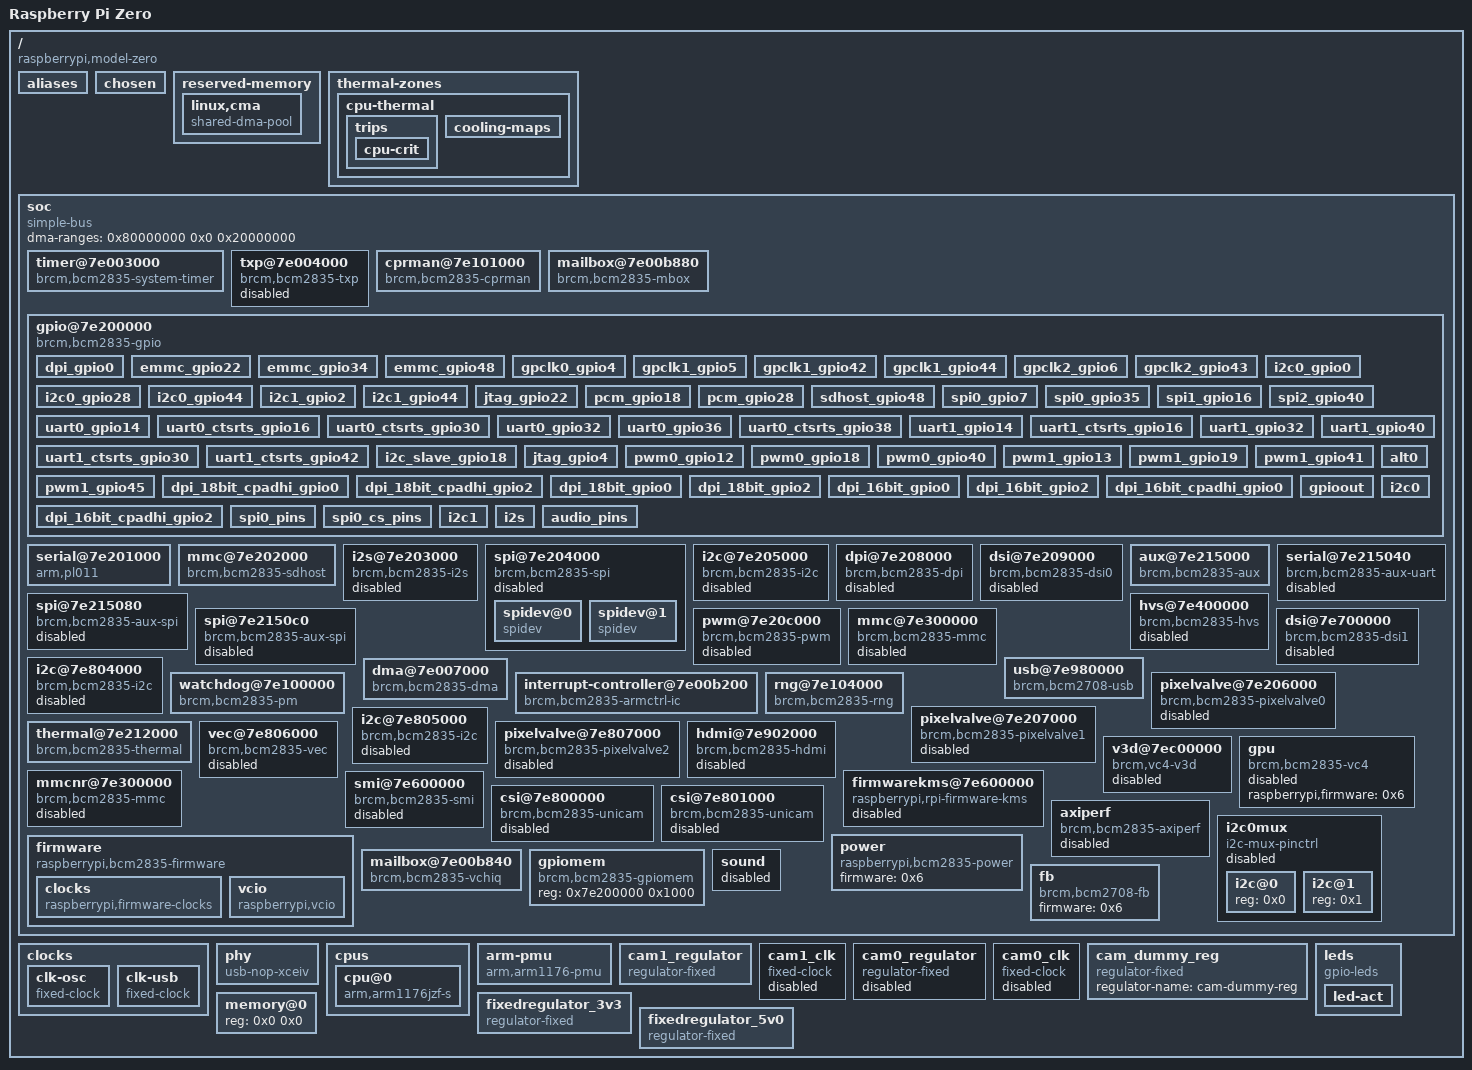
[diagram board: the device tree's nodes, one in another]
/dts-v1/;

/memreserve/	0x0000000000000000 0x0000000000001000;
/ {
	compatible = "raspberrypi,model-zero", "brcm,bcm2835";
	model = "Raspberry Pi Zero";
	#address-cells = <0x1>;
	#size-cells = <0x1>;
	interrupt-parent = <0x1>;

	aliases {
		serial0 = "/soc/serial@7e201000";
		serial1 = "/soc/serial@7e215040";
		aux = "/soc/aux@7e215000";
		sound = "/soc/sound";
		soc = "/soc";
		dma = "/soc/dma@7e007000";
		intc = "/soc/interrupt-controller@7e00b200";
		watchdog = "/soc/watchdog@7e100000";
		random = "/soc/rng@7e104000";
		mailbox = "/soc/mailbox@7e00b880";
		gpio = "/soc/gpio@7e200000";
		uart0 = "/soc/serial@7e201000";
		uart1 = "/soc/serial@7e215040";
		sdhost = "/soc/mmc@7e202000";
		mmc = "/soc/mmc@7e300000";
		mmc1 = "/soc/mmc@7e300000";
		mmc0 = "/soc/mmc@7e202000";
		i2s = "/soc/i2s@7e203000";
		i2c0 = "/soc/i2c0mux/i2c@0";
		i2c1 = "/soc/i2c@7e804000";
		i2c10 = "/soc/i2c0mux/i2c@1";
		spi0 = "/soc/spi@7e204000";
		spi1 = "/soc/spi@7e215080";
		spi2 = "/soc/spi@7e2150c0";
		usb = "/soc/usb@7e980000";
		leds = "/leds";
		fb = "/soc/fb";
		thermal = "/soc/thermal@7e212000";
		axiperf = "/soc/axiperf";
		i2c2 = "/soc/i2c@7e805000";
	};

	chosen {
		bootargs = "coherent_pool=1M snd_bcm2835.enable_headphones=0";
		phandle = <0x28>;
	};

	reserved-memory {
		#address-cells = <0x1>;
		#size-cells = <0x1>;
		ranges;
		phandle = <0x2a>;

		linux,cma {
			compatible = "shared-dma-pool";
			size = <0x4000000>;
			reusable;
			linux,cma-default;
			phandle = <0x2b>;
		};
	};

	thermal-zones {

		cpu-thermal {
			polling-delay-passive = <0x0>;
			polling-delay = <0x3e8>;
			thermal-sensors = <0x2>;
			coefficients = <0xfffffde6 0x635d8>;
			phandle = <0x2c>;

			trips {
				phandle = <0x2d>;

				cpu-crit {
					temperature = <0x1adb0>;
					hysteresis = <0x0>;
					type = "critical";
				};
			};

			cooling-maps {
				phandle = <0x2e>;
			};
		};
	};

	soc {
		compatible = "simple-bus";
		#address-cells = <0x1>;
		#size-cells = <0x1>;
		ranges = <0x7e000000 0x20000000 0x2000000>;
		dma-ranges = <0x80000000 0x0 0x20000000>;
		phandle = <0x2f>;

		timer@7e003000 {
			compatible = "brcm,bcm2835-system-timer";
			reg = <0x7e003000 0x1000>;
			interrupts = <0x1 0x0 0x1 0x1 0x1 0x2 0x1 0x3>;
			clock-frequency = <0xf4240>;
			phandle = <0x30>;
		};

		txp@7e004000 {
			compatible = "brcm,bcm2835-txp";
			reg = <0x7e004000 0x20>;
			interrupts = <0x1 0xb>;
			status = "disabled";
			phandle = <0x31>;
		};

		cprman@7e101000 {
			compatible = "brcm,bcm2835-cprman";
			#clock-cells = <0x1>;
			reg = <0x7e101000 0x2000>;
			clocks = <0x3 0x4 0x0 0x4 0x1 0x4 0x2 0x5 0x0 0x5 0x1 0x5 0x2>;
			firmware = <0x6>;
			phandle = <0x8>;
		};

		mailbox@7e00b880 {
			compatible = "brcm,bcm2835-mbox";
			reg = <0x7e00b880 0x40>;
			interrupts = <0x0 0x1>;
			#mbox-cells = <0x0>;
			phandle = <0x19>;
		};

		gpio@7e200000 {
			compatible = "brcm,bcm2835-gpio";
			reg = <0x7e200000 0xb4>;
			interrupts = <0x2 0x11 0x2 0x12>;
			gpio-controller;
			#gpio-cells = <0x2>;
			interrupt-controller;
			#interrupt-cells = <0x2>;
			gpio-ranges = <0x7 0x0 0x0 0x36>;
			pinctrl-names = "default";
			gpio-line-names = "ID_SDA", "ID_SCL", "SDA1", "SCL1", "GPIO_GCLK", "GPIO5", "GPIO6", "SPI_CE1_N", "SPI_CE0_N", "SPI_MISO", "SPI_MOSI", "SPI_SCLK", "GPIO12", "GPIO13", "TXD0", "RXD0", "GPIO16", "GPIO17", "GPIO18", "GPIO19", "GPIO20", "GPIO21", "GPIO22", "GPIO23", "GPIO24", "GPIO25", "GPIO26", "GPIO27", "SDA0", "SCL0", "NC", "NC", "CAM_GPIO1", "NC", "NC", "NC", "NC", "NC", "NC", "NC", "NC", "CAM_GPIO0", "NC", "NC", "NC", "NC", "HDMI_HPD_N", "STATUS_LED_N", "SD_CLK_R", "SD_CMD_R", "SD_DATA0_R", "SD_DATA1_R", "SD_DATA2_R", "SD_DATA3_R";
			phandle = <0x7>;

			dpi_gpio0 {
				brcm,pins = <0x0 0x1 0x2 0x3 0x4 0x5 0x6 0x7 0x8 0x9 0xa 0xb 0xc 0xd 0xe 0xf 0x10 0x11 0x12 0x13 0x14 0x15 0x16 0x17 0x18 0x19 0x1a 0x1b>;
				brcm,function = <0x6>;
				phandle = <0x32>;
			};

			emmc_gpio22 {
				brcm,pins = <0x16 0x17 0x18 0x19 0x1a 0x1b>;
				brcm,function = <0x7>;
				phandle = <0x33>;
			};

			emmc_gpio34 {
				brcm,pins = <0x22 0x23 0x24 0x25 0x26 0x27>;
				brcm,function = <0x7>;
				brcm,pull = <0x0 0x2 0x2 0x2 0x2 0x2>;
				phandle = <0x34>;
			};

			emmc_gpio48 {
				brcm,pins = <0x30 0x31 0x32 0x33 0x34 0x35>;
				brcm,function = <0x7>;
				phandle = <0x10>;
			};

			gpclk0_gpio4 {
				brcm,pins = <0x4>;
				brcm,function = <0x4>;
				phandle = <0x35>;
			};

			gpclk1_gpio5 {
				brcm,pins = <0x5>;
				brcm,function = <0x4>;
				phandle = <0x36>;
			};

			gpclk1_gpio42 {
				brcm,pins = <0x2a>;
				brcm,function = <0x4>;
				phandle = <0x37>;
			};

			gpclk1_gpio44 {
				brcm,pins = <0x2c>;
				brcm,function = <0x4>;
				phandle = <0x38>;
			};

			gpclk2_gpio6 {
				brcm,pins = <0x6>;
				brcm,function = <0x4>;
				phandle = <0x39>;
			};

			gpclk2_gpio43 {
				brcm,pins = <0x2b>;
				brcm,function = <0x4>;
				brcm,pull = <0x0>;
				phandle = <0x3a>;
			};

			i2c0_gpio0 {
				brcm,pins = <0x0 0x1>;
				brcm,function = <0x4>;
				phandle = <0x17>;
			};

			i2c0_gpio28 {
				brcm,pins = <0x1c 0x1d>;
				brcm,function = <0x4>;
				phandle = <0x18>;
			};

			i2c0_gpio44 {
				brcm,pins = <0x2c 0x2d>;
				brcm,function = <0x5>;
				phandle = <0x3b>;
			};

			i2c1_gpio2 {
				brcm,pins = <0x2 0x3>;
				brcm,function = <0x4>;
				phandle = <0x3c>;
			};

			i2c1_gpio44 {
				brcm,pins = <0x2c 0x2d>;
				brcm,function = <0x6>;
				phandle = <0x3d>;
			};

			jtag_gpio22 {
				brcm,pins = <0x16 0x17 0x18 0x19 0x1a 0x1b>;
				brcm,function = <0x3>;
				phandle = <0x3e>;
			};

			pcm_gpio18 {
				brcm,pins = <0x12 0x13 0x14 0x15>;
				brcm,function = <0x4>;
				phandle = <0x3f>;
			};

			pcm_gpio28 {
				brcm,pins = <0x1c 0x1d 0x1e 0x1f>;
				brcm,function = <0x6>;
				phandle = <0x40>;
			};

			sdhost_gpio48 {
				brcm,pins = <0x30 0x31 0x32 0x33 0x34 0x35>;
				brcm,function = <0x4>;
				phandle = <0xa>;
			};

			spi0_gpio7 {
				brcm,pins = <0x7 0x8 0x9 0xa 0xb>;
				brcm,function = <0x4>;
				phandle = <0x41>;
			};

			spi0_gpio35 {
				brcm,pins = <0x23 0x24 0x25 0x26 0x27>;
				brcm,function = <0x4>;
				phandle = <0x42>;
			};

			spi1_gpio16 {
				brcm,pins = <0x10 0x11 0x12 0x13 0x14 0x15>;
				brcm,function = <0x3>;
				phandle = <0x43>;
			};

			spi2_gpio40 {
				brcm,pins = <0x28 0x29 0x2a 0x2b 0x2c 0x2d>;
				brcm,function = <0x3>;
				phandle = <0x44>;
			};

			uart0_gpio14 {
				brcm,pins = <0xe 0xf>;
				brcm,function = <0x4>;
				phandle = <0x45>;
			};

			uart0_ctsrts_gpio16 {
				brcm,pins = <0x10 0x11>;
				brcm,function = <0x7>;
				phandle = <0x46>;
			};

			uart0_ctsrts_gpio30 {
				brcm,pins = <0x1e 0x1f>;
				brcm,function = <0x7>;
				brcm,pull = <0x2 0x0>;
				phandle = <0x47>;
			};

			uart0_gpio32 {
				brcm,pins = <0x20 0x21>;
				brcm,function = <0x7>;
				brcm,pull = <0x0 0x2>;
				phandle = <0x48>;
			};

			uart0_gpio36 {
				brcm,pins = <0x24 0x25>;
				brcm,function = <0x6>;
				phandle = <0x49>;
			};

			uart0_ctsrts_gpio38 {
				brcm,pins = <0x26 0x27>;
				brcm,function = <0x6>;
				phandle = <0x4a>;
			};

			uart1_gpio14 {
				brcm,pins = <0xe 0xf>;
				brcm,function = <0x2>;
				phandle = <0x4b>;
			};

			uart1_ctsrts_gpio16 {
				brcm,pins = <0x10 0x11>;
				brcm,function = <0x2>;
				phandle = <0x4c>;
			};

			uart1_gpio32 {
				brcm,pins = <0x20 0x21>;
				brcm,function = <0x2>;
				phandle = <0x4d>;
			};

			uart1_ctsrts_gpio30 {
				brcm,pins = <0x1e 0x1f>;
				brcm,function = <0x2>;
				phandle = <0x4e>;
			};

			uart1_gpio40 {
				brcm,pins = <0x28 0x29>;
				brcm,function = <0x2>;
				phandle = <0x4f>;
			};

			uart1_ctsrts_gpio42 {
				brcm,pins = <0x2a 0x2b>;
				brcm,function = <0x2>;
				phandle = <0x50>;
			};

			i2c_slave_gpio18 {
				brcm,pins = <0x12 0x13 0x14 0x15>;
				brcm,function = <0x7>;
				phandle = <0x51>;
			};

			jtag_gpio4 {
				brcm,pins = <0x4 0x5 0x6 0xc 0xd>;
				brcm,function = <0x2>;
				phandle = <0x52>;
			};

			pwm0_gpio12 {
				brcm,pins = <0xc>;
				brcm,function = <0x4>;
				phandle = <0x53>;
			};

			pwm0_gpio18 {
				brcm,pins = <0x12>;
				brcm,function = <0x2>;
				phandle = <0x54>;
			};

			pwm0_gpio40 {
				brcm,pins = <0x28>;
				brcm,function = <0x4>;
				phandle = <0x55>;
			};

			pwm1_gpio13 {
				brcm,pins = <0xd>;
				brcm,function = <0x4>;
				phandle = <0x56>;
			};

			pwm1_gpio19 {
				brcm,pins = <0x13>;
				brcm,function = <0x2>;
				phandle = <0x57>;
			};

			pwm1_gpio41 {
				brcm,pins = <0x29>;
				brcm,function = <0x4>;
				phandle = <0x58>;
			};

			pwm1_gpio45 {
				brcm,pins = <0x2d>;
				brcm,function = <0x4>;
				phandle = <0x59>;
			};

			dpi_18bit_cpadhi_gpio0 {
				brcm,pins = <0x0 0x1 0x2 0x3 0x4 0x5 0x6 0x7 0x8 0x9 0xc 0xd 0xe 0xf 0x10 0x11 0x14 0x15 0x16 0x17 0x18 0x19>;
				brcm,function = <0x6>;
				brcm,pull = <0x0>;
				phandle = <0x5a>;
			};

			dpi_18bit_cpadhi_gpio2 {
				brcm,pins = <0x2 0x3 0x4 0x5 0x6 0x7 0x8 0x9 0xc 0xd 0xe 0xf 0x10 0x11 0x14 0x15 0x16 0x17 0x18 0x19>;
				brcm,function = <0x6>;
				phandle = <0x5b>;
			};

			dpi_18bit_gpio0 {
				brcm,pins = <0x0 0x1 0x2 0x3 0x4 0x5 0x6 0x7 0x8 0x9 0xa 0xb 0xc 0xd 0xe 0xf 0x10 0x11 0x12 0x13 0x14 0x15>;
				brcm,function = <0x6>;
				phandle = <0x5c>;
			};

			dpi_18bit_gpio2 {
				brcm,pins = <0x2 0x3 0x4 0x5 0x6 0x7 0x8 0x9 0xa 0xb 0xc 0xd 0xe 0xf 0x10 0x11 0x12 0x13 0x14 0x15>;
				brcm,function = <0x6>;
				phandle = <0x5d>;
			};

			dpi_16bit_gpio0 {
				brcm,pins = <0x0 0x1 0x2 0x3 0x4 0x5 0x6 0x7 0x8 0x9 0xa 0xb 0xc 0xd 0xe 0xf 0x10 0x11 0x12 0x13>;
				brcm,function = <0x6>;
				phandle = <0x5e>;
			};

			dpi_16bit_gpio2 {
				brcm,pins = <0x2 0x3 0x4 0x5 0x6 0x7 0x8 0x9 0xa 0xb 0xc 0xd 0xe 0xf 0x10 0x11 0x12 0x13>;
				brcm,function = <0x6>;
				phandle = <0x5f>;
			};

			dpi_16bit_cpadhi_gpio0 {
				brcm,pins = <0x0 0x1 0x2 0x3 0x4 0x5 0x6 0x7 0x8 0xc 0xd 0xe 0xf 0x10 0x11 0x14 0x15 0x16 0x17 0x18>;
				brcm,function = <0x6>;
				phandle = <0x60>;
			};

			dpi_16bit_cpadhi_gpio2 {
				brcm,pins = <0x2 0x3 0x4 0x5 0x6 0x7 0x8 0xc 0xd 0xe 0xf 0x10 0x11 0x14 0x15 0x16 0x17 0x18>;
				brcm,function = <0x6>;
				phandle = <0x61>;
			};

			gpioout {
				brcm,pins = <0x6>;
				brcm,function = <0x1>;
				phandle = <0x62>;
			};

			alt0 {
				brcm,pins = <0x4 0x5 0x7 0x8 0x9 0xa 0xb>;
				brcm,function = <0x4>;
				phandle = <0x63>;
			};

			spi0_pins {
				brcm,pins = <0x9 0xa 0xb>;
				brcm,function = <0x4>;
				phandle = <0xc>;
			};

			spi0_cs_pins {
				brcm,pins = <0x8 0x7>;
				brcm,function = <0x1>;
				phandle = <0xd>;
			};

			i2c0 {
				brcm,pins = <0x0 0x1>;
				brcm,function = <0x4>;
				phandle = <0x64>;
			};

			i2c1 {
				brcm,pins = <0x2 0x3>;
				brcm,function = <0x4>;
				phandle = <0x11>;
			};

			i2s {
				brcm,pins = <0x12 0x13 0x14 0x15>;
				brcm,function = <0x4>;
				phandle = <0xb>;
			};

			audio_pins {
				brcm,pins;
				brcm,function;
				phandle = <0x1a>;
			};
		};

		serial@7e201000 {
			compatible = "arm,pl011", "arm,primecell";
			reg = <0x7e201000 0x200>;
			interrupts = <0x2 0x19>;
			clocks = <0x8 0x13 0x8 0x14>;
			clock-names = "uartclk", "apb_pclk";
			arm,primecell-periphid = <0x241011>;
			cts-event-workaround;
			skip-init;
			status = "okay";
			phandle = <0x1b>;
		};

		mmc@7e202000 {
			compatible = "brcm,bcm2835-sdhost";
			reg = <0x7e202000 0x100>;
			interrupts = <0x2 0x18>;
			clocks = <0x8 0x14>;
			status = "okay";
			dmas = <0x9 0x2000000d>;
			dma-names = "rx-tx";
			bus-width = <0x4>;
			brcm,overclock-50 = <0x0>;
			brcm,pio-limit = <0x1>;
			firmware = <0x6>;
			pinctrl-names = "default";
			pinctrl-0 = <0xa>;
			phandle = <0x23>;
		};

		i2s@7e203000 {
			compatible = "brcm,bcm2835-i2s";
			reg = <0x7e203000 0x24>;
			clocks = <0x8 0x1f>;
			status = "disabled";
			dmas = <0x9 0x2 0x9 0x3>;
			dma-names = "tx", "rx";
			#sound-dai-cells = <0x0>;
			pinctrl-names = "default";
			pinctrl-0 = <0xb>;
			phandle = <0x1d>;
		};

		spi@7e204000 {
			compatible = "brcm,bcm2835-spi";
			reg = <0x7e204000 0x200>;
			interrupts = <0x2 0x16>;
			clocks = <0x8 0x14>;
			#address-cells = <0x1>;
			#size-cells = <0x0>;
			status = "disabled";
			dmas = <0x9 0x6 0x9 0x7>;
			dma-names = "tx", "rx";
			pinctrl-names = "default";
			pinctrl-0 = <0xc 0xd>;
			cs-gpios = <0x7 0x8 0x1 0x7 0x7 0x1>;
			phandle = <0x1e>;

			spidev@0 {
				compatible = "spidev";
				reg = <0x0>;
				#address-cells = <0x1>;
				#size-cells = <0x0>;
				spi-max-frequency = <0x7735940>;
				phandle = <0x65>;
			};

			spidev@1 {
				compatible = "spidev";
				reg = <0x1>;
				#address-cells = <0x1>;
				#size-cells = <0x0>;
				spi-max-frequency = <0x7735940>;
				phandle = <0x66>;
			};
		};

		i2c@7e205000 {
			compatible = "brcm,bcm2835-i2c";
			reg = <0x7e205000 0x200>;
			interrupts = <0x2 0x15>;
			clocks = <0x8 0x14>;
			#address-cells = <0x1>;
			#size-cells = <0x0>;
			status = "disabled";
			clock-frequency = <0x186a0>;
			phandle = <0x16>;
		};

		dpi@7e208000 {
			compatible = "brcm,bcm2835-dpi";
			reg = <0x7e208000 0x8c>;
			clocks = <0x8 0x14 0x8 0x2c>;
			clock-names = "core", "pixel";
			status = "disabled";
			phandle = <0x67>;
		};

		dsi@7e209000 {
			compatible = "brcm,bcm2835-dsi0";
			reg = <0x7e209000 0x78>;
			interrupts = <0x2 0x4>;
			#address-cells = <0x1>;
			#size-cells = <0x0>;
			#clock-cells = <0x1>;
			clocks = <0x8 0x20 0x8 0x2f 0x8 0x31>;
			clock-names = "phy", "escape", "pixel";
			clock-output-names = "dsi0_byte", "dsi0_ddr2", "dsi0_ddr";
			status = "disabled";
			power-domains = <0xe 0x11>;
			phandle = <0x4>;
		};

		aux@7e215000 {
			compatible = "brcm,bcm2835-aux";
			#clock-cells = <0x1>;
			reg = <0x7e215000 0x8>;
			clocks = <0x8 0x14>;
			phandle = <0xf>;
		};

		serial@7e215040 {
			compatible = "brcm,bcm2835-aux-uart";
			reg = <0x7e215040 0x40>;
			interrupts = <0x1 0x1d>;
			clocks = <0xf 0x0>;
			status = "disabled";
			skip-init;
			phandle = <0x1c>;
		};

		spi@7e215080 {
			compatible = "brcm,bcm2835-aux-spi";
			reg = <0x7e215080 0x40>;
			interrupts = <0x1 0x1d>;
			clocks = <0xf 0x1>;
			#address-cells = <0x1>;
			#size-cells = <0x0>;
			status = "disabled";
			phandle = <0x68>;
		};

		spi@7e2150c0 {
			compatible = "brcm,bcm2835-aux-spi";
			reg = <0x7e2150c0 0x40>;
			interrupts = <0x1 0x1d>;
			clocks = <0xf 0x2>;
			#address-cells = <0x1>;
			#size-cells = <0x0>;
			status = "disabled";
			phandle = <0x69>;
		};

		pwm@7e20c000 {
			compatible = "brcm,bcm2835-pwm";
			reg = <0x7e20c000 0x28>;
			clocks = <0x8 0x1e>;
			assigned-clocks = <0x8 0x1e>;
			assigned-clock-rates = <0x989680>;
			#pwm-cells = <0x2>;
			status = "disabled";
			phandle = <0x6a>;
		};

		mmc@7e300000 {
			compatible = "brcm,bcm2835-mmc", "brcm,bcm2835-sdhci";
			reg = <0x7e300000 0x100>;
			interrupts = <0x2 0x1e>;
			clocks = <0x8 0x1c>;
			status = "disabled";
			dmas = <0x9 0xb>;
			dma-names = "rx-tx";
			brcm,overclock-50 = <0x0>;
			pinctrl-names = "default";
			pinctrl-0 = <0x10>;
			bus-width = <0x4>;
			phandle = <0x24>;
		};

		hvs@7e400000 {
			compatible = "brcm,bcm2835-hvs";
			reg = <0x7e400000 0x6000>;
			interrupts = <0x2 0x1>;
			status = "disabled";
			phandle = <0x6b>;
		};

		dsi@7e700000 {
			compatible = "brcm,bcm2835-dsi1";
			reg = <0x7e700000 0x8c>;
			interrupts = <0x2 0xc>;
			#address-cells = <0x1>;
			#size-cells = <0x0>;
			#clock-cells = <0x1>;
			clocks = <0x8 0x23 0x8 0x30 0x8 0x32>;
			clock-names = "phy", "escape", "pixel";
			clock-output-names = "dsi1_byte", "dsi1_ddr2", "dsi1_ddr";
			status = "disabled";
			power-domains = <0xe 0x12>;
			phandle = <0x5>;
		};

		i2c@7e804000 {
			compatible = "brcm,bcm2835-i2c";
			reg = <0x7e804000 0x1000>;
			interrupts = <0x2 0x15>;
			clocks = <0x8 0x14>;
			#address-cells = <0x1>;
			#size-cells = <0x0>;
			status = "disabled";
			pinctrl-names = "default";
			pinctrl-0 = <0x11>;
			clock-frequency = <0x186a0>;
			phandle = <0x20>;
		};

		usb@7e980000 {
			compatible = "brcm,bcm2708-usb";
			reg = <0x7e980000 0x10000 0x7e006000 0x1000>;
			interrupts = <0x1 0x9 0x2 0x0>;
			#address-cells = <0x1>;
			#size-cells = <0x0>;
			clocks = <0x12>;
			clock-names = "otg";
			phys = <0x13>;
			phy-names = "usb2-phy";
			interrupt-names = "usb", "soft";
			power-domains = <0xe 0x6>;
			phandle = <0x6c>;
		};

		dma@7e007000 {
			compatible = "brcm,bcm2835-dma";
			reg = <0x7e007000 0xf00>;
			interrupts = <0x1 0x10 0x1 0x11 0x1 0x12 0x1 0x13 0x1 0x14 0x1 0x15 0x1 0x16 0x1 0x17 0x1 0x18 0x1 0x19 0x1 0x1a 0x1 0x1b 0x1 0x1b 0x1 0x1b 0x1 0x1b 0x1 0x1c>;
			interrupt-names = "dma0", "dma1", "dma2", "dma3", "dma4", "dma5", "dma6", "dma7", "dma8", "dma9", "dma10", "dma11", "dma12", "dma13", "dma14", "dma-shared-all";
			#dma-cells = <0x1>;
			brcm,dma-channel-mask = <0x7f35>;
			phandle = <0x9>;
		};

		interrupt-controller@7e00b200 {
			compatible = "brcm,bcm2835-armctrl-ic";
			reg = <0x7e00b200 0x200>;
			interrupt-controller;
			#interrupt-cells = <0x2>;
			phandle = <0x1>;
		};

		watchdog@7e100000 {
			compatible = "brcm,bcm2835-pm", "brcm,bcm2835-pm-wdt";
			#power-domain-cells = <0x1>;
			#reset-cells = <0x1>;
			reg = <0x7e100000 0x114 0x7e00a000 0x24>;
			reg-names = "pm", "asb";
			clocks = <0x8 0x15 0x8 0x1d 0x8 0x17 0x8 0x16>;
			clock-names = "v3d", "peri_image", "h264", "isp";
			system-power-controller;
			phandle = <0x21>;
		};

		rng@7e104000 {
			compatible = "brcm,bcm2835-rng";
			reg = <0x7e104000 0x10>;
			interrupts = <0x2 0x1d>;
			phandle = <0x22>;
		};

		pixelvalve@7e206000 {
			compatible = "brcm,bcm2835-pixelvalve0";
			reg = <0x7e206000 0x100>;
			interrupts = <0x2 0xd>;
			status = "disabled";
			phandle = <0x6d>;
		};

		pixelvalve@7e207000 {
			compatible = "brcm,bcm2835-pixelvalve1";
			reg = <0x7e207000 0x100>;
			interrupts = <0x2 0xe>;
			status = "disabled";
			phandle = <0x6e>;
		};

		thermal@7e212000 {
			compatible = "brcm,bcm2835-thermal";
			reg = <0x7e212000 0x8>;
			clocks = <0x8 0x1b>;
			#thermal-sensor-cells = <0x0>;
			status = "okay";
			phandle = <0x2>;
		};

		i2c@7e805000 {
			compatible = "brcm,bcm2835-i2c";
			reg = <0x7e805000 0x1000>;
			interrupts = <0x2 0x15>;
			clocks = <0x8 0x14>;
			#address-cells = <0x1>;
			#size-cells = <0x0>;
			status = "disabled";
			clock-frequency = <0x186a0>;
			phandle = <0x15>;
		};

		vec@7e806000 {
			compatible = "brcm,bcm2835-vec";
			reg = <0x7e806000 0x1000>;
			clocks = <0x14 0xf>;
			interrupts = <0x2 0x1b>;
			status = "disabled";
			power-domains = <0xe 0x7>;
			phandle = <0x6f>;
		};

		pixelvalve@7e807000 {
			compatible = "brcm,bcm2835-pixelvalve2";
			reg = <0x7e807000 0x100>;
			interrupts = <0x2 0xa>;
			status = "disabled";
			phandle = <0x70>;
		};

		hdmi@7e902000 {
			compatible = "brcm,bcm2835-hdmi";
			reg = <0x7e902000 0x600 0x7e808000 0x100>;
			interrupts = <0x2 0x8 0x2 0x9>;
			ddc = <0x15>;
			clocks = <0x14 0x9 0x14 0xd>;
			clock-names = "pixel", "hdmi";
			dmas = <0x9 0x9000011>;
			dma-names = "audio-rx";
			status = "disabled";
			reg-names = "hdmi", "hd";
			power-domains = <0xe 0x5>;
			hpd-gpios = <0x7 0x2e 0x1>;
			phandle = <0x27>;
		};

		v3d@7ec00000 {
			compatible = "brcm,vc4-v3d";
			reg = <0x7ec00000 0x1000>;
			interrupts = <0x1 0xa>;
			power-domains = <0xe 0xa>;
			status = "disabled";
			phandle = <0x71>;
		};

		gpu {
			compatible = "brcm,bcm2835-vc4";
			status = "disabled";
			raspberrypi,firmware = <0x6>;
			phandle = <0x72>;
		};

		mmcnr@7e300000 {
			compatible = "brcm,bcm2835-mmc", "brcm,bcm2835-sdhci";
			reg = <0x7e300000 0x100>;
			interrupts = <0x2 0x1e>;
			clocks = <0x8 0x1c>;
			dmas = <0x9 0xb>;
			dma-names = "rx-tx";
			brcm,overclock-50 = <0x0>;
			non-removable;
			status = "disabled";
			phandle = <0x25>;
		};

		firmwarekms@7e600000 {
			compatible = "raspberrypi,rpi-firmware-kms";
			reg = <0x7e600000 0x100>;
			interrupts = <0x2 0x10>;
			brcm,firmware = <0x6>;
			status = "disabled";
			phandle = <0x73>;
		};

		smi@7e600000 {
			compatible = "brcm,bcm2835-smi";
			reg = <0x7e600000 0x100>;
			interrupts = <0x2 0x10>;
			clocks = <0x8 0x2a>;
			assigned-clocks = <0x8 0x2a>;
			assigned-clock-rates = <0x7735940>;
			dmas = <0x9 0x4>;
			dma-names = "rx-tx";
			status = "disabled";
			phandle = <0x74>;
		};

		csi@7e800000 {
			compatible = "brcm,bcm2835-unicam";
			reg = <0x7e800000 0x800 0x7e802000 0x4>;
			interrupts = <0x2 0x6>;
			clocks = <0x8 0x2d 0x14 0x4>;
			clock-names = "lp", "vpu";
			power-domains = <0xe 0xc>;
			#address-cells = <0x1>;
			#size-cells = <0x0>;
			#clock-cells = <0x1>;
			status = "disabled";
			phandle = <0x75>;
		};

		csi@7e801000 {
			compatible = "brcm,bcm2835-unicam";
			reg = <0x7e801000 0x800 0x7e802004 0x4>;
			interrupts = <0x2 0x7>;
			clocks = <0x8 0x2e 0x14 0x4>;
			clock-names = "lp", "vpu";
			power-domains = <0xe 0xd>;
			#address-cells = <0x1>;
			#size-cells = <0x0>;
			#clock-cells = <0x1>;
			status = "disabled";
			brcm,num-data-lanes = <0x2>;
			phandle = <0x76>;
		};

		axiperf {
			compatible = "brcm,bcm2835-axiperf";
			reg = <0x7e009800 0x100 0x7ee08000 0x100>;
			firmware = <0x6>;
			status = "disabled";
			phandle = <0x26>;
		};

		i2c0mux {
			compatible = "i2c-mux-pinctrl";
			#address-cells = <0x1>;
			#size-cells = <0x0>;
			i2c-parent = <0x16>;
			status = "disabled";
			pinctrl-names = "i2c0", "i2c_csi_dsi";
			pinctrl-0 = <0x17>;
			pinctrl-1 = <0x18>;
			phandle = <0x1f>;

			i2c@0 {
				reg = <0x0>;
				#address-cells = <0x1>;
				#size-cells = <0x0>;
				phandle = <0x77>;
			};

			i2c@1 {
				reg = <0x1>;
				#address-cells = <0x1>;
				#size-cells = <0x0>;
				phandle = <0x78>;
			};
		};

		firmware {
			compatible = "raspberrypi,bcm2835-firmware", "simple-mfd";
			#address-cells = <0x1>;
			#size-cells = <0x1>;
			mboxes = <0x19>;
			dma-ranges;
			phandle = <0x6>;

			clocks {
				compatible = "raspberrypi,firmware-clocks";
				#clock-cells = <0x1>;
				phandle = <0x14>;
			};

			vcio {
				compatible = "raspberrypi,vcio";
				phandle = <0x79>;
			};
		};

		power {
			compatible = "raspberrypi,bcm2835-power";
			firmware = <0x6>;
			#power-domain-cells = <0x1>;
			phandle = <0xe>;
		};

		mailbox@7e00b840 {
			compatible = "brcm,bcm2835-vchiq";
			reg = <0x7e00b840 0x3c>;
			interrupts = <0x0 0x2>;
			pinctrl-names = "default";
			pinctrl-0 = <0x1a>;
			phandle = <0x7a>;
		};

		gpiomem {
			compatible = "brcm,bcm2835-gpiomem";
			reg = <0x7e200000 0x1000>;
		};

		fb {
			compatible = "brcm,bcm2708-fb";
			firmware = <0x6>;
			status = "okay";
			phandle = <0x7b>;
		};

		sound {
			status = "disabled";
			phandle = <0x7c>;
		};
	};

	clocks {

		clk-osc {
			compatible = "fixed-clock";
			#clock-cells = <0x0>;
			clock-output-names = "osc";
			clock-frequency = <0x124f800>;
			phandle = <0x3>;
		};

		clk-usb {
			compatible = "fixed-clock";
			#clock-cells = <0x0>;
			clock-output-names = "otg";
			clock-frequency = <0x1c9c3800>;
			phandle = <0x12>;
		};
	};

	phy {
		compatible = "usb-nop-xceiv";
		#phy-cells = <0x0>;
		phandle = <0x13>;
	};

	cpus {
		#address-cells = <0x1>;
		#size-cells = <0x0>;

		cpu@0 {
			device_type = "cpu";
			compatible = "arm,arm1176jzf-s";
			reg = <0x0>;
			d-cache-size = <0x4000>;
			d-cache-line-size = <0x10>;
			d-cache-sets = <0x100>;
			i-cache-size = <0x4000>;
			i-cache-line-size = <0x10>;
			i-cache-sets = <0x100>;
		};
	};

	arm-pmu {
		compatible = "arm,arm1176-pmu";
	};

	cam1_regulator {
		compatible = "regulator-fixed";
		regulator-name = "cam1-reg";
		enable-active-high;
		status = "okay";
		gpio = <0x7 0x29 0x0>;
		phandle = <0x7d>;
	};

	cam1_clk {
		compatible = "fixed-clock";
		#clock-cells = <0x0>;
		status = "disabled";
		phandle = <0x7e>;
	};

	cam0_regulator {
		compatible = "regulator-fixed";
		regulator-name = "cam0-reg";
		enable-active-high;
		status = "disabled";
		phandle = <0x7f>;
	};

	cam0_clk {
		compatible = "fixed-clock";
		#clock-cells = <0x0>;
		status = "disabled";
		phandle = <0x80>;
	};

	cam_dummy_reg {
		compatible = "regulator-fixed";
		regulator-name = "cam-dummy-reg";
		status = "okay";
		phandle = <0x81>;
	};

	__overrides__ {
		cam0-pwdn-ctrl;
		cam0-pwdn;
		cam0-led-ctrl;
		cam0-led;
		arm_freq;
		cache_line_size;
		uart0 = [00 00 00 1b 73 74 61 74 75 73 00];
		uart1 = [00 00 00 1c 73 74 61 74 75 73 00];
		i2s = [00 00 00 1d 73 74 61 74 75 73 00];
		spi = [00 00 00 1e 73 74 61 74 75 73 00];
		i2c0 = [00 00 00 16 73 74 61 74 75 73 00 00 00 00 1f 73 74 61 74 75 73 00];
		i2c1 = "", "", "", " status";
		i2c0_baudrate = [00 00 00 16 63 6c 6f 63 6b 2d 66 72 65 71 75 65 6e 63 79 3a 30 00];
		i2c1_baudrate = "", "", "", " clock-frequency:0";
		watchdog = "", "", "", "!status";
		random = "", "", "", "\"status";
		sd_overclock = "", "", "", "#brcm,overclock-50:0";
		sd_force_pio = "", "", "", "#brcm,force-pio?";
		sd_pio_limit = "", "", "", "#brcm,pio-limit:0";
		sd_debug = "", "", "", "#brcm,debug";
		sdio_overclock = "", "", "", "$brcm,overclock-50:0", "", "", "", "%brcm,overclock-50:0";
		axiperf = "", "", "", "&status";
		hdmi = "", "", "", "'status";
		i2c2_iknowwhatimdoing = [00 00 00 15 73 74 61 74 75 73 00];
		i2c2_baudrate = [00 00 00 15 63 6c 6f 63 6b 2d 66 72 65 71 75 65 6e 63 79 3a 30 00];
		sd = "", "", "", "#status";
		sd_poll_once = "", "", "", "#non-removable?";
		audio = "", "", "", "(bootargs{on='snd_bcm2835.enable_hdmi=1',off='snd_bcm2835.enable_hdmi=0'}";
		act_led_gpio = "", "", "", ")gpios:4";
		act_led_activelow = "", "", "", ")gpios:8";
		act_led_trigger = "", "", "", ")linux,default-trigger";
	};

	leds {
		compatible = "gpio-leds";
		phandle = <0x82>;

		led-act {
			label = "ACT";
			default-state = "off";
			linux,default-trigger = "actpwr";
			gpios = <0x7 0x2f 0x1>;
			phandle = <0x29>;
		};
	};

	fixedregulator_3v3 {
		compatible = "regulator-fixed";
		regulator-always-on;
		regulator-max-microvolt = <0x325aa0>;
		regulator-min-microvolt = <0x325aa0>;
		regulator-name = "3v3";
		phandle = <0x83>;
	};

	fixedregulator_5v0 {
		compatible = "regulator-fixed";
		regulator-always-on;
		regulator-max-microvolt = <0x4c4b40>;
		regulator-min-microvolt = <0x4c4b40>;
		regulator-name = "5v0";
		phandle = <0x84>;
	};

	memory@0 {
		device_type = "memory";
		reg = <0x0 0x0>;
	};

	__symbols__ {
		chosen = "/chosen";
		rmem = "/reserved-memory";
		cma = "/reserved-memory/linux,cma";
		cpu_thermal = "/thermal-zones/cpu-thermal";
		thermal_trips = "/thermal-zones/cpu-thermal/trips";
		cooling_maps = "/thermal-zones/cpu-thermal/cooling-maps";
		soc = "/soc";
		system_timer = "/soc/timer@7e003000";
		txp = "/soc/txp@7e004000";
		clocks = "/soc/cprman@7e101000";
		mailbox = "/soc/mailbox@7e00b880";
		gpio = "/soc/gpio@7e200000";
		dpi_gpio0 = "/soc/gpio@7e200000/dpi_gpio0";
		emmc_gpio22 = "/soc/gpio@7e200000/emmc_gpio22";
		emmc_gpio34 = "/soc/gpio@7e200000/emmc_gpio34";
		emmc_gpio48 = "/soc/gpio@7e200000/emmc_gpio48";
		gpclk0_gpio4 = "/soc/gpio@7e200000/gpclk0_gpio4";
		gpclk1_gpio5 = "/soc/gpio@7e200000/gpclk1_gpio5";
		gpclk1_gpio42 = "/soc/gpio@7e200000/gpclk1_gpio42";
		gpclk1_gpio44 = "/soc/gpio@7e200000/gpclk1_gpio44";
		gpclk2_gpio6 = "/soc/gpio@7e200000/gpclk2_gpio6";
		gpclk2_gpio43 = "/soc/gpio@7e200000/gpclk2_gpio43";
		i2c0_gpio0 = "/soc/gpio@7e200000/i2c0_gpio0";
		i2c0_gpio28 = "/soc/gpio@7e200000/i2c0_gpio28";
		i2c0_gpio44 = "/soc/gpio@7e200000/i2c0_gpio44";
		i2c1_gpio2 = "/soc/gpio@7e200000/i2c1_gpio2";
		i2c1_gpio44 = "/soc/gpio@7e200000/i2c1_gpio44";
		jtag_gpio22 = "/soc/gpio@7e200000/jtag_gpio22";
		pcm_gpio18 = "/soc/gpio@7e200000/pcm_gpio18";
		pcm_gpio28 = "/soc/gpio@7e200000/pcm_gpio28";
		sdhost_gpio48 = "/soc/gpio@7e200000/sdhost_gpio48";
		spi0_gpio7 = "/soc/gpio@7e200000/spi0_gpio7";
		spi0_gpio35 = "/soc/gpio@7e200000/spi0_gpio35";
		spi1_gpio16 = "/soc/gpio@7e200000/spi1_gpio16";
		spi2_gpio40 = "/soc/gpio@7e200000/spi2_gpio40";
		uart0_gpio14 = "/soc/gpio@7e200000/uart0_gpio14";
		uart0_ctsrts_gpio16 = "/soc/gpio@7e200000/uart0_ctsrts_gpio16";
		uart0_ctsrts_gpio30 = "/soc/gpio@7e200000/uart0_ctsrts_gpio30";
		uart0_gpio32 = "/soc/gpio@7e200000/uart0_gpio32";
		uart0_gpio36 = "/soc/gpio@7e200000/uart0_gpio36";
		uart0_ctsrts_gpio38 = "/soc/gpio@7e200000/uart0_ctsrts_gpio38";
		uart1_gpio14 = "/soc/gpio@7e200000/uart1_gpio14";
		uart1_ctsrts_gpio16 = "/soc/gpio@7e200000/uart1_ctsrts_gpio16";
		uart1_gpio32 = "/soc/gpio@7e200000/uart1_gpio32";
		uart1_ctsrts_gpio30 = "/soc/gpio@7e200000/uart1_ctsrts_gpio30";
		uart1_gpio40 = "/soc/gpio@7e200000/uart1_gpio40";
		uart1_ctsrts_gpio42 = "/soc/gpio@7e200000/uart1_ctsrts_gpio42";
		i2c_slave_gpio18 = "/soc/gpio@7e200000/i2c_slave_gpio18";
		jtag_gpio4 = "/soc/gpio@7e200000/jtag_gpio4";
		pwm0_gpio12 = "/soc/gpio@7e200000/pwm0_gpio12";
		pwm0_gpio18 = "/soc/gpio@7e200000/pwm0_gpio18";
		pwm0_gpio40 = "/soc/gpio@7e200000/pwm0_gpio40";
		pwm1_gpio13 = "/soc/gpio@7e200000/pwm1_gpio13";
		pwm1_gpio19 = "/soc/gpio@7e200000/pwm1_gpio19";
		pwm1_gpio41 = "/soc/gpio@7e200000/pwm1_gpio41";
		pwm1_gpio45 = "/soc/gpio@7e200000/pwm1_gpio45";
		dpi_18bit_cpadhi_gpio0 = "/soc/gpio@7e200000/dpi_18bit_cpadhi_gpio0";
		dpi_18bit_cpadhi_gpio2 = "/soc/gpio@7e200000/dpi_18bit_cpadhi_gpio2";
		dpi_18bit_gpio0 = "/soc/gpio@7e200000/dpi_18bit_gpio0";
		dpi_18bit_gpio2 = "/soc/gpio@7e200000/dpi_18bit_gpio2";
		dpi_16bit_gpio0 = "/soc/gpio@7e200000/dpi_16bit_gpio0";
		dpi_16bit_gpio2 = "/soc/gpio@7e200000/dpi_16bit_gpio2";
		dpi_16bit_cpadhi_gpio0 = "/soc/gpio@7e200000/dpi_16bit_cpadhi_gpio0";
		dpi_16bit_cpadhi_gpio2 = "/soc/gpio@7e200000/dpi_16bit_cpadhi_gpio2";
		gpioout = "/soc/gpio@7e200000/gpioout";
		alt0 = "/soc/gpio@7e200000/alt0";
		spi0_pins = "/soc/gpio@7e200000/spi0_pins";
		spi0_cs_pins = "/soc/gpio@7e200000/spi0_cs_pins";
		i2c0_pins = "/soc/gpio@7e200000/i2c0";
		i2c1_pins = "/soc/gpio@7e200000/i2c1";
		i2s_pins = "/soc/gpio@7e200000/i2s";
		audio_pins = "/soc/gpio@7e200000/audio_pins";
		uart0 = "/soc/serial@7e201000";
		sdhost = "/soc/mmc@7e202000";
		i2s = "/soc/i2s@7e203000";
		spi0 = "/soc/spi@7e204000";
		spi = "/soc/spi@7e204000";
		spidev0 = "/soc/spi@7e204000/spidev@0";
		spidev1 = "/soc/spi@7e204000/spidev@1";
		i2c0if = "/soc/i2c@7e205000";
		dpi = "/soc/dpi@7e208000";
		dsi0 = "/soc/dsi@7e209000";
		aux = "/soc/aux@7e215000";
		uart1 = "/soc/serial@7e215040";
		spi1 = "/soc/spi@7e215080";
		spi2 = "/soc/spi@7e2150c0";
		pwm = "/soc/pwm@7e20c000";
		mmc = "/soc/mmc@7e300000";
		sdhci = "/soc/mmc@7e300000";
		hvs = "/soc/hvs@7e400000";
		dsi1 = "/soc/dsi@7e700000";
		i2c1 = "/soc/i2c@7e804000";
		usb = "/soc/usb@7e980000";
		dma = "/soc/dma@7e007000";
		intc = "/soc/interrupt-controller@7e00b200";
		watchdog = "/soc/watchdog@7e100000";
		pm = "/soc/watchdog@7e100000";
		random = "/soc/rng@7e104000";
		pixelvalve0 = "/soc/pixelvalve@7e206000";
		pixelvalve1 = "/soc/pixelvalve@7e207000";
		thermal = "/soc/thermal@7e212000";
		i2c2 = "/soc/i2c@7e805000";
		vec = "/soc/vec@7e806000";
		pixelvalve2 = "/soc/pixelvalve@7e807000";
		hdmi = "/soc/hdmi@7e902000";
		v3d = "/soc/v3d@7ec00000";
		vc4 = "/soc/gpu";
		mmcnr = "/soc/mmcnr@7e300000";
		firmwarekms = "/soc/firmwarekms@7e600000";
		smi = "/soc/smi@7e600000";
		csi0 = "/soc/csi@7e800000";
		csi1 = "/soc/csi@7e801000";
		axiperf = "/soc/axiperf";
		i2c0mux = "/soc/i2c0mux";
		i2c0 = "/soc/i2c0mux/i2c@0";
		i2c_csi_dsi = "/soc/i2c0mux/i2c@1";
		firmware = "/soc/firmware";
		firmware_clocks = "/soc/firmware/clocks";
		vcio = "/soc/firmware/vcio";
		power = "/soc/power";
		vchiq = "/soc/mailbox@7e00b840";
		fb = "/soc/fb";
		sound = "/soc/sound";
		clk_osc = "/clocks/clk-osc";
		clk_usb = "/clocks/clk-usb";
		usbphy = "/phy";
		cam1_reg = "/cam1_regulator";
		cam1_clk = "/cam1_clk";
		cam0_regulator = "/cam0_regulator";
		cam0_clk = "/cam0_clk";
		cam0_reg = "/cam_dummy_reg";
		cam_dummy_reg = "/cam_dummy_reg";
		leds = "/leds";
		act_led = "/leds/led-act";
		vdd_3v3_reg = "/fixedregulator_3v3";
		vdd_5v0_reg = "/fixedregulator_5v0";
	};
};
